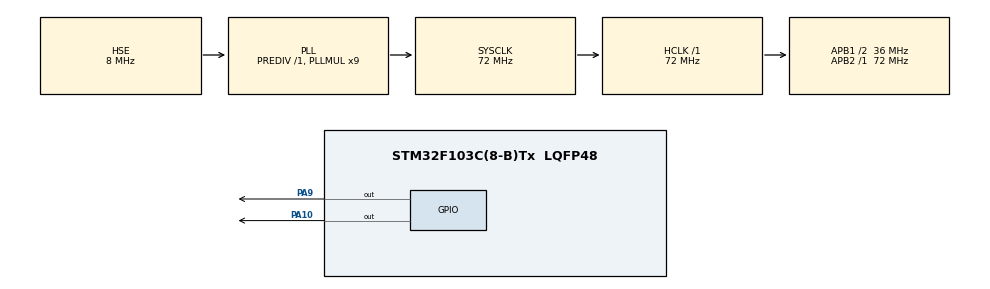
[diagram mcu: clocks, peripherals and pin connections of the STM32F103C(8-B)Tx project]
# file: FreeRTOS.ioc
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Mcu.Family=STM32F1
RCC.PLLSourceVirtual=RCC_PLLSOURCE_HSE
FREERTOS.Tasks01=defaultTask,0,128,StartDefaultTask,Default,NULL,Dynamic,NULL,NULL
PD1-OSC_OUT.Mode=HSE-External-Oscillator
PD0-OSC_IN.Signal=RCC_OSC_IN
RCC.APB1CLKDivider=RCC_HCLK_DIV2
RCC.SYSCLKSource=RCC_SYSCLKSOURCE_PLLCLK
ProjectManager.StackSize=0x400
PD1-OSC_OUT.Signal=RCC_OSC_OUT
PA13.Signal=SYS_JTMS-SWDIO
ProjectManager.TargetToolchain=MDK-ARM V5.27
RCC.HCLKFreq_Value=72000000
RCC.APB2TimFreq_Value=72000000
PA9.Signal=GPIO_Output
RCC.USBFreq_Value=72000000
RCC.AHBFreq_Value=72000000
PD0-OSC_IN.Mode=HSE-External-Oscillator
board=custom
RCC.PLLMUL=RCC_PLL_MUL9
RCC.APB2Freq_Value=72000000
PA14.Mode=Serial_Wire
VP_FREERTOS_VS_CMSIS_V1.Mode=CMSIS_V1
PA13.Mode=Serial_Wire
Mcu.Name=STM32F103C(8-B)Tx
FREERTOS.configTOTAL_HEAP_SIZE=15360
RCC.SYSCLKFreq_VALUE=72000000
Mcu.Package=LQFP48
PA10.Signal=GPIO_Output
PA14.Signal=SYS_JTCK-SWCLK
ProjectManager.HeapSize=0x200
NVIC.PriorityGroup=NVIC_PRIORITYGROUP_4
RCC.APB1TimFreq_Value=72000000
RCC.APB1Freq_Value=36000000

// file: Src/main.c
/* USER CODE BEGIN Header */
/**
  ******************************************************************************
  * @file           : main.c
  * @brief          : Main program body
  ******************************************************************************
  * @attention
  *
  * <h2><center>&copy; Copyright (c) 2020 STMicroelectronics.
  * All rights reserved.</center></h2>
  *
  * This software component is licensed by ST under Ultimate Liberty license
  * SLA0044, the "License"; You may not use this file except in compliance with
  * the License. You may obtain a copy of the License at:
  *                             www.st.com/SLA0044
  *
  ******************************************************************************
  */
/* USER CODE END Header */

#include "main.h"
#include "cmsis_os.h"

osThreadId defaultTaskHandle;

void SystemClock_Config(void);
static void MX_GPIO_Init(void);
void StartDefaultTasknew(void const * argument);
void StartDefaultTask(void const * argument);

int main(void)
{

  /* MCU Configuration--------------------------------------------------------*/

  /* Reset of all peripherals, Initializes the Flash interface and the Systick. */
  HAL_Init();

  /* Configure the system clock */
  SystemClock_Config();

  /* Initialize all configured peripherals */
  MX_GPIO_Init();

  osThreadDef(defaultTasknew, StartDefaultTasknew, osPriorityNormal, 0, 1024);
  defaultTaskHandle = osThreadCreate(osThread(defaultTasknew), NULL);
  /* Create the thread(s) */
  /* definition and creation of defaultTask */
  osThreadDef(defaultTask, StartDefaultTask, osPriorityNormal, 0, 128);
  defaultTaskHandle = osThreadCreate(osThread(defaultTask), NULL);

  /* Start scheduler */
  osKernelStart();

  /* We should never get here as control is now taken by the scheduler */
  /* Infinite loop */
  while (1)
  {

  }
}

void SystemClock_Config(void)
{
  RCC_OscInitTypeDef RCC_OscInitStruct = {0};
  RCC_ClkInitTypeDef RCC_ClkInitStruct = {0};

  /** Initializes the CPU, AHB and APB busses clocks
  */
  RCC_OscInitStruct.OscillatorType = RCC_OSCILLATORTYPE_HSE;
  RCC_OscInitStruct.HSEState = RCC_HSE_ON;
  RCC_OscInitStruct.HSEPredivValue = RCC_HSE_PREDIV_DIV1;
  RCC_OscInitStruct.HSIState = RCC_HSI_ON;
  RCC_OscInitStruct.PLL.PLLState = RCC_PLL_ON;
  RCC_OscInitStruct.PLL.PLLSource = RCC_PLLSOURCE_HSE;
  RCC_OscInitStruct.PLL.PLLMUL = RCC_PLL_MUL9;
  if (HAL_RCC_OscConfig(&RCC_OscInitStruct) != HAL_OK)
  {
    Error_Handler();
  }
  /** Initializes the CPU, AHB and APB busses clocks
  */
  RCC_ClkInitStruct.ClockType = RCC_CLOCKTYPE_HCLK|RCC_CLOCKTYPE_SYSCLK
                              |RCC_CLOCKTYPE_PCLK1|RCC_CLOCKTYPE_PCLK2;
  RCC_ClkInitStruct.SYSCLKSource = RCC_SYSCLKSOURCE_PLLCLK;
  RCC_ClkInitStruct.AHBCLKDivider = RCC_SYSCLK_DIV1;
  RCC_ClkInitStruct.APB1CLKDivider = RCC_HCLK_DIV2;
  RCC_ClkInitStruct.APB2CLKDivider = RCC_HCLK_DIV1;

  if (HAL_RCC_ClockConfig(&RCC_ClkInitStruct, FLASH_LATENCY_2) != HAL_OK)
  {
    Error_Handler();
  }
}

static void MX_GPIO_Init(void)
{
  GPIO_InitTypeDef GPIO_InitStruct = {0};

  /* GPIO Ports Clock Enable */
  __HAL_RCC_GPIOD_CLK_ENABLE();
  __HAL_RCC_GPIOA_CLK_ENABLE();

  /*Configure GPIO pin Output Level */
  HAL_GPIO_WritePin(GPIOA, GPIO_PIN_9|GPIO_PIN_10, GPIO_PIN_RESET);

  /*Configure GPIO pins : PA9 PA10 */
  GPIO_InitStruct.Pin = GPIO_PIN_9|GPIO_PIN_10;
  GPIO_InitStruct.Mode = GPIO_MODE_OUTPUT_PP;
  GPIO_InitStruct.Pull = GPIO_NOPULL;
  GPIO_InitStruct.Speed = GPIO_SPEED_FREQ_LOW;
  HAL_GPIO_Init(GPIOA, &GPIO_InitStruct);

}

/* USER CODE BEGIN 4 */
void StartDefaultTasknew(void const * argument)
{
	for(;;)
  {
		HAL_GPIO_TogglePin(GPIOA,GPIO_PIN_9);
    osDelay(100);
  }
}
/* USER CODE END 4 */

void StartDefaultTask(void const * argument)
{
  /* USER CODE BEGIN 5 */
  /* Infinite loop */
  for(;;)
  {
		HAL_GPIO_TogglePin(GPIOA,GPIO_PIN_10);
    osDelay(1000);
  }
  /* USER CODE END 5 */
}

void Error_Handler(void)
{
}

/************************ (C) COPYRIGHT STMicroelectronics *****END OF FILE****/
